# N32H488 register map
Vendor: Nationstech Ltd.; File version: 1.0
Registers are 32-bit, read-write, reset 0x0 unless marked. A register's access mark holds for its fields unless they carry their own. Offsets are from the block's base; [hi:lo] are bit positions; {n}, {i} and the like mark numbered series.

## RCC
Base 0x40021000
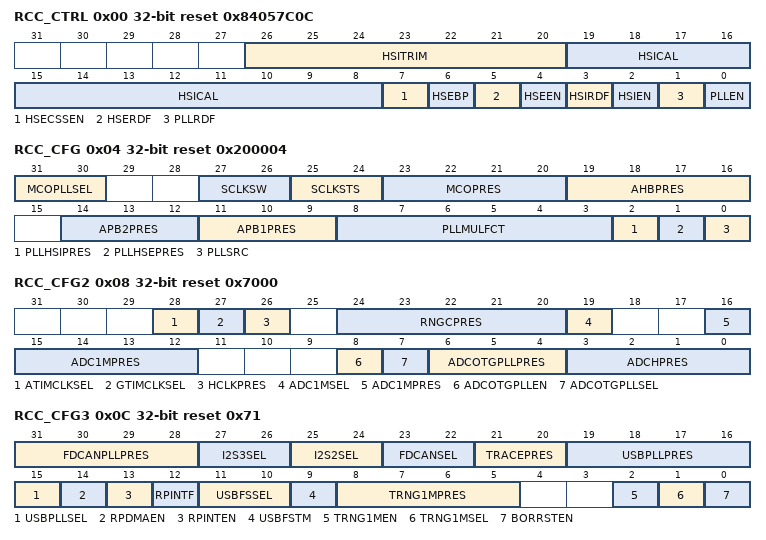
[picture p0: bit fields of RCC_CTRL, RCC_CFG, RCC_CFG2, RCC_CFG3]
0x00 RCC_CTRL reset 0x84057C0C
  [26:20] HSITRIM, [19:8] HSICAL, [7] HSECSSEN, [6] HSEBP, [5] HSERDF, [4] HSEEN, [3] HSIRDF, [2] HSIEN, [1] PLLRDF, [0] PLLEN
0x04 RCC_CFG reset 0x200004
  [31:30] MCOPLLSEL, [27:26] SCLKSW, [25:24] SCLKSTS, [23:20] MCOPRES, [19:16] AHBPRES, [14:12] APB2PRES, [11:9] APB1PRES, [8:3] PLLMULFCT, [2] PLLHSIPRES, [1] PLLHSEPRES, [0] PLLSRC
0x08 RCC_CFG2 reset 0x7000
  [28] ATIMCLKSEL, [27] GTIMCLKSEL, [26] HCLKPRES, [24:20] RNGCPRES, [19] ADC1MSEL, [16:12] ADC1MPRES, [8] ADCOTGPLLEN, [7] ADCOTGPLLSEL, [6:4] ADCOTGPLLPRES, [3:0] ADCHPRES
0x0C RCC_CFG3 reset 0x71
  [31:28] FDCANPLLPRES, [27:26] I2S3SEL, [25:24] I2S2SEL, [23:22] FDCANSEL, [21:20] TRACEPRES, [19:16] USBPLLPRES, [15] USBPLLSEL, [14] RPDMAEN, [13] RPINTEN, [12] RPINTF, [11:10] USBFSSEL, [9] USBFSTM, [8:5] TRNG1MPRES, [2] TRNG1MEN, [1] TRNG1MSEL, [0] BORRSTEN
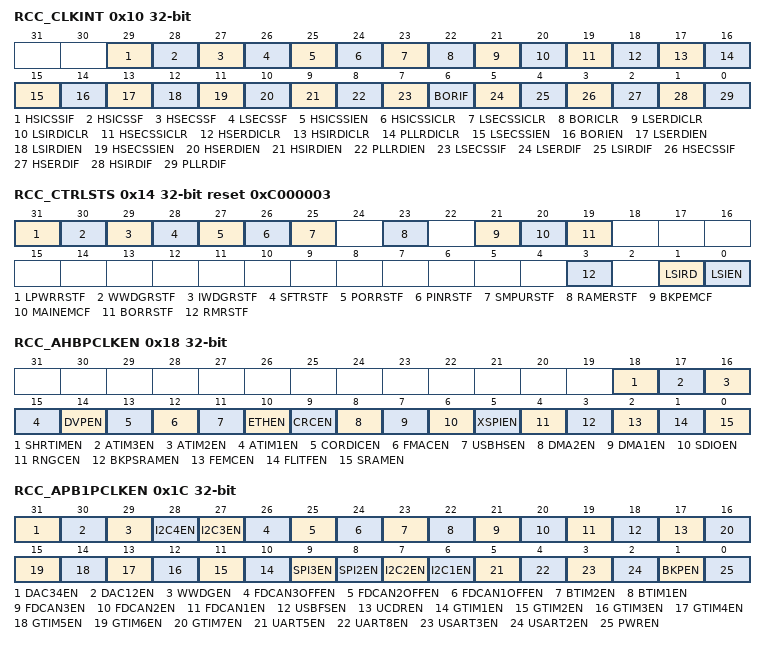
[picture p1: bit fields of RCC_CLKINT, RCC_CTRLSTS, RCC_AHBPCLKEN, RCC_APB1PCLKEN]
0x10 RCC_CLKINT
  [29] HSICSSIF, [28] HSICSSF, [27] HSECSSF, [26] LSECSSF, [25] HSICSSIEN, [24] HSICSSICLR, [23] LSECSSICLR, [22] BORICLR, [21] LSERDICLR, [20] LSIRDICLR, [19] HSECSSICLR, [18] HSERDICLR, [17] HSIRDICLR, [16] PLLRDICLR, [15] LSECSSIEN, [14] BORIEN, [13] LSERDIEN, [12] LSIRDIEN, [11] HSECSSIEN, [10] HSERDIEN, [9] HSIRDIEN, [8] PLLRDIEN, [7] LSECSSIF, [6] BORIF, [5] LSERDIF, [4] LSIRDIF, [3] HSECSSIF, [2] HSERDIF, [1] HSIRDIF, [0] PLLRDIF
0x14 RCC_CTRLSTS reset 0xC000003
  [31] LPWRRSTF, [30] WWDGRSTF, [29] IWDGRSTF, [28] SFTRSTF, [27] PORRSTF, [26] PINRSTF, [25] SMPURSTF, [23] RAMERSTF, [21] BKPEMCF, [20] MAINEMCF, [19] BORRSTF, [3] RMRSTF, [1] LSIRD, [0] LSIEN
0x18 RCC_AHBPCLKEN
  [18] SHRTIMEN, [17] ATIM3EN, [16] ATIM2EN, [15] ATIM1EN, [14] DVPEN, [13] CORDICEN, [12] FMACEN, [11] USBHSEN, [10] ETHEN, [9] CRCEN, [8] DMA2EN, [7] DMA1EN, [6] SDIOEN, [5] XSPIEN, [4] RNGCEN, [3] BKPSRAMEN, [2] FEMCEN, [1] FLITFEN, [0] SRAMEN
0x1C RCC_APB1PCLKEN
  [31] DAC34EN, [30] DAC12EN, [29] WWDGEN, [28] I2C4EN, [27] I2C3EN, [26] FDCAN3OFFEN, [25] FDCAN2OFFEN, [24] FDCAN1OFFEN, [23] BTIM2EN, [22] BTIM1EN, [21] FDCAN3EN, [20] FDCAN2EN, [19] FDCAN1EN, [18] USBFSEN, [17] UCDREN, [n+9] GTIM{n}EN (n=1..7), [9] SPI3EN, [8] SPI2EN, [7] I2C2EN, [6] I2C1EN, [5] UART5EN, [4] UART8EN, [3] USART3EN, [2] USART2EN, [1] BKPEN, [0] PWREN
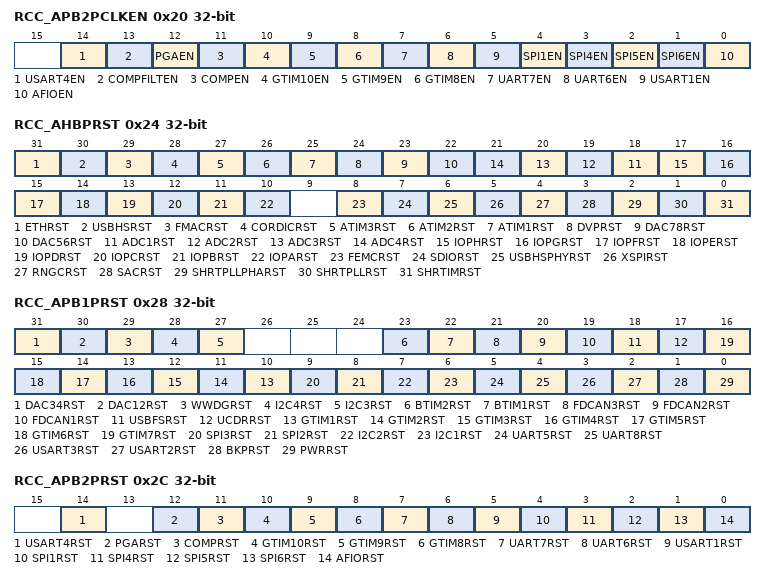
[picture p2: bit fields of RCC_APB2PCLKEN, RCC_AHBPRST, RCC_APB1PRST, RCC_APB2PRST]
0x20 RCC_APB2PCLKEN
  [14] USART4EN, [13] COMPFILTEN, [12] PGAEN, [11] COMPEN, [10] GTIM10EN, [9] GTIM9EN, [8] GTIM8EN, [7] UART7EN, [6] UART6EN, [5] USART1EN, [4] SPI1EN, [3] SPI4EN, [2] SPI5EN, [1] SPI6EN, [0] AFIOEN
0x24 RCC_AHBPRST
  [31] ETHRST, [30] USBHSRST, [29] FMACRST, [28] CORDICRST, [27] ATIM3RST, [26] ATIM2RST, [25] ATIM1RST, [24] DVPRST, [23] DAC78RST, [22] DAC56RST, [n+17] ADC{n}RST (n=1..4), [17] IOPHRST, [16] IOPGRST, [15] IOPFRST, [14] IOPERST, [13] IOPDRST, [12] IOPCRST, [11] IOPBRST, [10] IOPARST, [8] FEMCRST, [7] SDIORST, [6] USBHSPHYRST, [5] XSPIRST, [4] RNGCRST, [3] SACRST, [2] SHRTPLLPHARST, [1] SHRTPLLRST, [0] SHRTIMRST
0x28 RCC_APB1PRST
  [31] DAC34RST, [30] DAC12RST, [29] WWDGRST, [28] I2C4RST, [27] I2C3RST, [23] BTIM2RST, [22] BTIM1RST, [21] FDCAN3RST, [20] FDCAN2RST, [19] FDCAN1RST, [18] USBFSRST, [17] UCDRRST, [n+9] GTIM{n}RST (n=1..7), [9] SPI3RST, [8] SPI2RST, [7] I2C2RST, [6] I2C1RST, [5] UART5RST, [4] UART8RST, [3] USART3RST, [2] USART2RST, [1] BKPRST, [0] PWRRST
0x2C RCC_APB2PRST
  [14] USART4RST, [12] PGARST, [11] COMPRST, [10] GTIM10RST, [9] GTIM9RST, [8] GTIM8RST, [7] UART7RST, [6] UART6RST, [5] USART1RST, [4] SPI1RST, [3] SPI4RST, [2] SPI5RST, [1] SPI6RST, [0] AFIORST
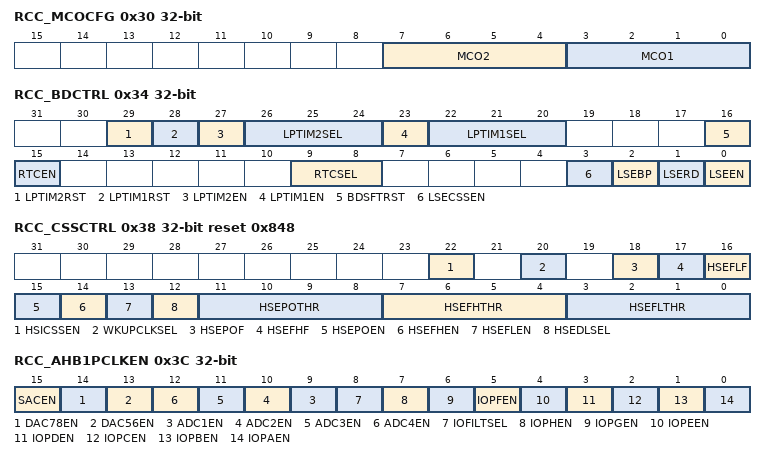
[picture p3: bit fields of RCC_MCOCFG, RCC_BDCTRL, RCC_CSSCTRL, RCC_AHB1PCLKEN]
0x30 RCC_MCOCFG
  [7:4] MCO2, [3:0] MCO1
0x34 RCC_BDCTRL
  [29] LPTIM2RST, [28] LPTIM1RST, [27] LPTIM2EN, [26:24] LPTIM2SEL, [23] LPTIM1EN, [22:20] LPTIM1SEL, [16] BDSFTRST, [15] RTCEN, [9:8] RTCSEL, [3] LSECSSEN, [2] LSEBP, [1] LSERD, [0] LSEEN
0x38 RCC_CSSCTRL reset 0x848
  [22] HSICSSEN, [20] WKUPCLKSEL, [18] HSEPOF, [17] HSEFHF, [16] HSEFLF, [15] HSEPOEN, [14] HSEFHEN, [13] HSEFLEN, [12] HSEDLSEL, [11:8] HSEPOTHR, [7:4] HSEFHTHR, [3:0] HSEFLTHR
0x3C RCC_AHB1PCLKEN
  [15] SACEN, [14] DAC78EN, [13] DAC56EN, [n+8] ADC{n}EN (n=1..4), [8] IOFILTSEL, [7] IOPHEN, [6] IOPGEN, [5] IOPFEN, [4] IOPEEN, [3] IOPDEN, [2] IOPCEN, [1] IOPBEN, [0] IOPAEN
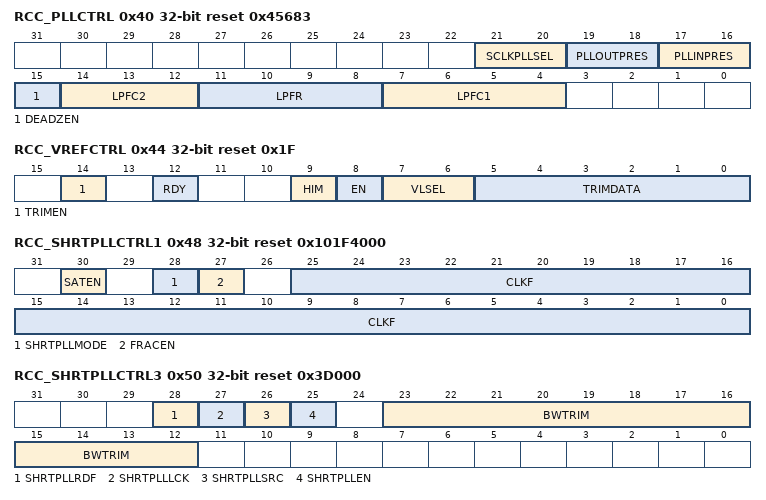
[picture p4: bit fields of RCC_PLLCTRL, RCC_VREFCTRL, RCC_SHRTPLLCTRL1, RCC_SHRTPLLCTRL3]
0x40 RCC_PLLCTRL reset 0x45683
  [21:20] SCLKPLLSEL, [19:18] PLLOUTPRES, [17:16] PLLINPRES, [15] DEADZEN, [14:12] LPFC2, [11:8] LPFR, [7:4] LPFC1
0x44 RCC_VREFCTRL reset 0x1F
  [14] TRIMEN, [12] RDY, [9] HIM, [8] EN, [7:6] VLSEL, [5:0] TRIMDATA
0x48 RCC_SHRTPLLCTRL1 reset 0x101F4000
  [30] SATEN, [28] SHRTPLLMODE, [27] FRACEN, [25:0] CLKF
0x4C RCC_SHRTPLLCTRL2 reset 0x848
  [31:26] CLKR
0x50 RCC_SHRTPLLCTRL3 reset 0x3D000
  [28] SHRTPLLRDF, [27] SHRTPLLLCK, [26] SHRTPLLSRC, [25] SHRTPLLEN, [23:12] BWTRIM
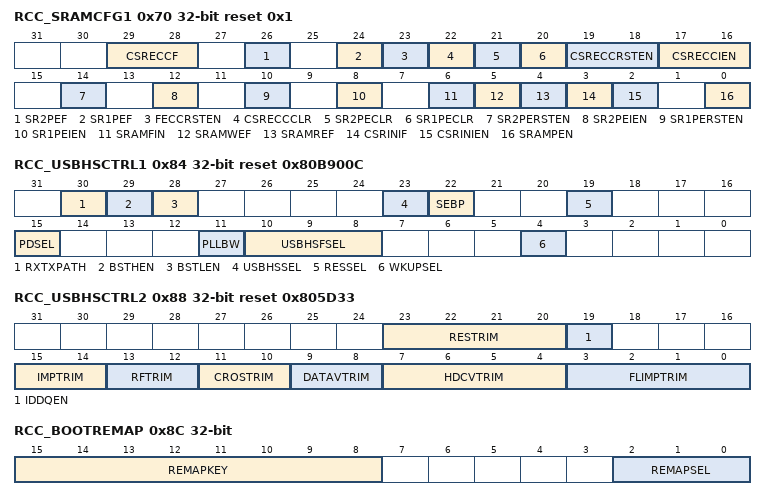
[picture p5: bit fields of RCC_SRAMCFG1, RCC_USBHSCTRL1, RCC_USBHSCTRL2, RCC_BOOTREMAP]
0x70 RCC_SRAMCFG1 reset 0x1
  [29:28] CSRECCF, [26] SR2PEF, [24] SR1PEF, [23] FECCRSTEN, [22] CSRECCCLR, [21] SR2PECLR, [20] SR1PECLR, [19:18] CSRECCRSTEN, [17:16] CSRECCIEN, [14] SR2PERSTEN, [12] SR2PEIEN, [10] SR1PERSTEN, [8] SR1PEIEN, [6] SRAMFIN, [5] SRAMWEF, [4] SRAMREF, [3] CSRINIF, [2] CSRINIEN, [0] SRAMPEN
0x74 RCC_SRAMCFG2
  [31:0] INIDAT
0x78 RCC_SRAMCFG3
  [31:0] INISTART
0x7C RCC_SRAMCFG4
  [31:0] INIEND
0x84 RCC_USBHSCTRL1 reset 0x80B900C
  [30] RXTXPATH, [29] BSTHEN, [28] BSTLEN, [23] USBHSSEL, [22] SEBP, [19] RESSEL, [15] PDSEL, [11] PLLBW, [10:8] USBHSFSEL, [4] WKUPSEL
0x88 RCC_USBHSCTRL2 reset 0x805D33
  [23:20] RESTRIM, [19] IDDQEN, [15:14] IMPTRIM, [13:12] RFTRIM, [11:10] CROSTRIM, [9:8] DATAVTRIM, [7:4] HDCVTRIM, [3:0] FLIMPTRIM
0x8C RCC_BOOTREMAP
  [15:8] REMAPKEY, [2:0] REMAPSEL
0x90 RCC_FDCANBADDR reset 0x20000000
  [31:0] BADDR
